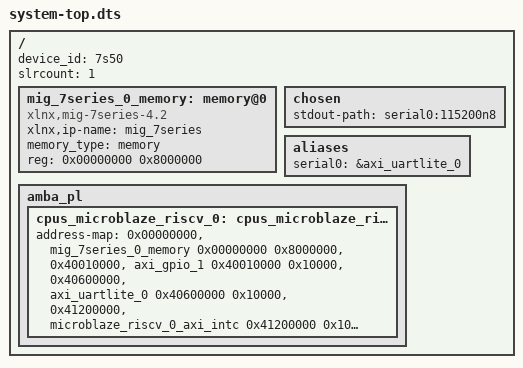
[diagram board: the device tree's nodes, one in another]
/dts-v1/;
#include "pl.dtsi"
/ {
	device_id = "7s50";
	#address-cells = <1>;
	#size-cells = <1>;
	slrcount = <1>;
	mig_7series_0_memory: memory@0 {
		compatible = "xlnx,mig-7series-4.2";
		xlnx,ip-name = "mig_7series";
		device_type = "memory";
		memory_type = "memory";
		reg = <0x00000000 0x8000000>;
	};
	chosen {
		stdout-path = "serial0:115200n8";
	};
	aliases {
		serial0 = &axi_uartlite_0;
	};
	amba_pl: amba_pl {
		cpus_microblaze_riscv_0: cpus_microblaze_riscv@0 {
			address-map = <0x00000000 &mig_7series_0_memory 0x00000000 0x8000000>, 
			      <0x40010000 &axi_gpio_1 0x40010000 0x10000>, 
			      <0x40600000 &axi_uartlite_0 0x40600000 0x10000>, 
			      <0x41200000 &microblaze_riscv_0_axi_intc 0x41200000 0x10000>;
			#ranges-address-cells = <0x1>;
			#ranges-size-cells = <0x1>;
		};
	};
};
